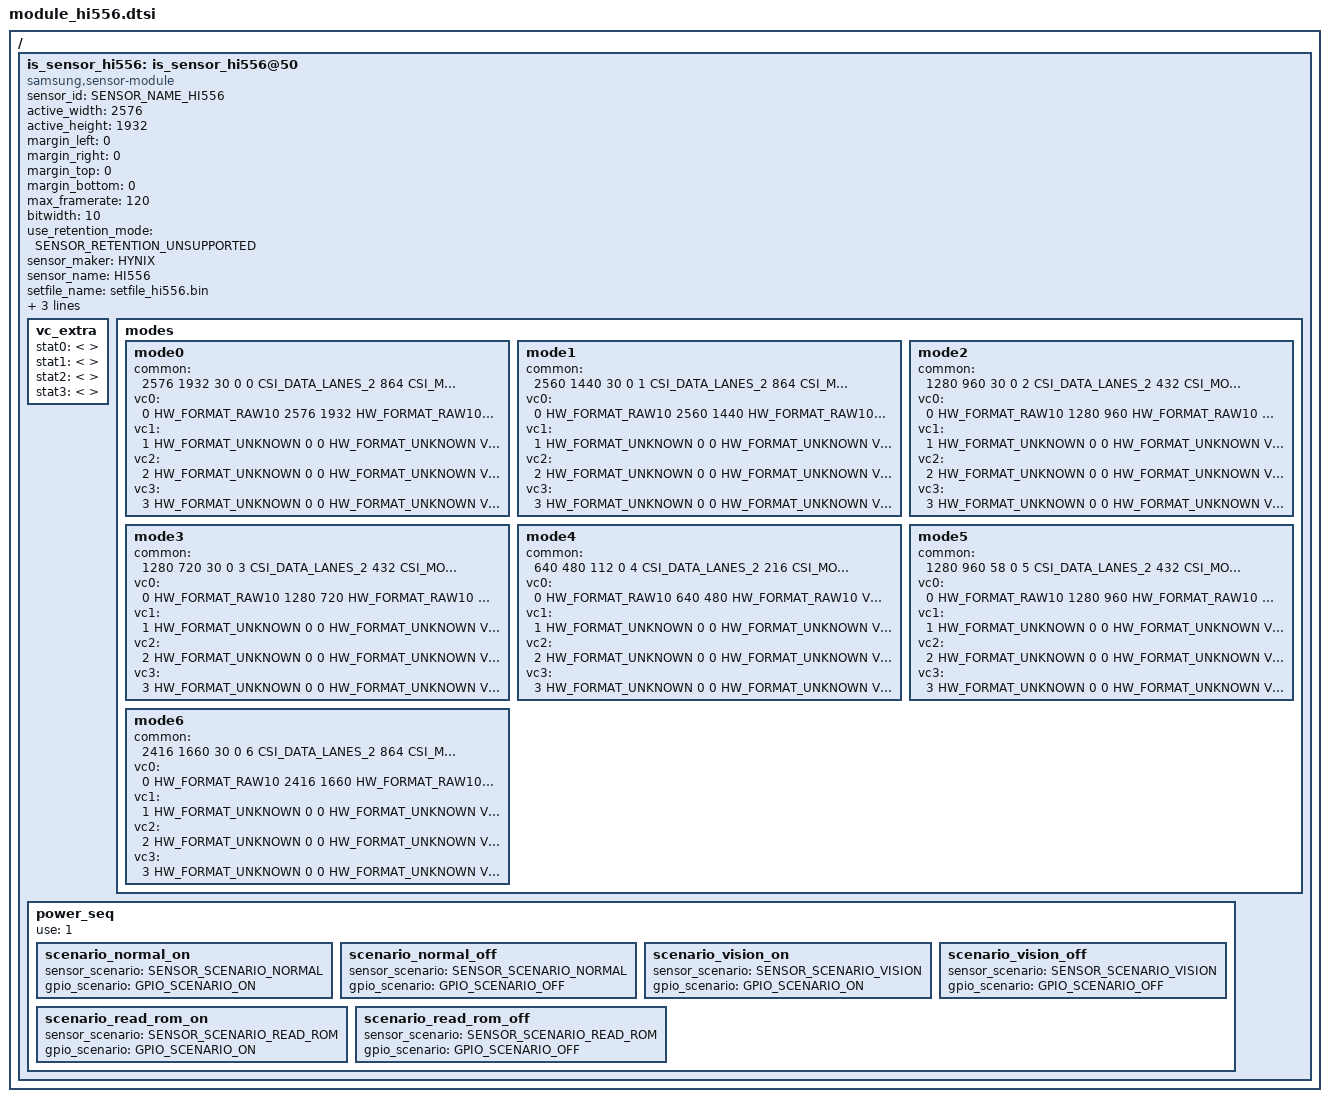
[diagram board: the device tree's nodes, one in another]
/*
 * SAMSUNG EXYNOSxxxx board camera device tree source
 *
 * Copyright (c) 2022 Samsung Electronics Co., Ltd.
 *		http://www.samsung.com
 *
 * This program is free software; you can redistribute it and/or modify
 * it under the terms of the GNU General Public License version 2 as
 * published by the Free Software Foundation.
 */

#include <dt-bindings/camera/exynos_is_dt.h>

#ifndef USE_VENDOR_PWR_PIN_NAME
#define HI556_IOVDD	<>
#define HI556_AVDD	<>
#define HI556_DVDD	<>
#endif

/ {
	fragment@camera {
		target-path = "/";
		__overlay__ {
			is_sensor_hi556: is_sensor_hi556@50 {
				compatible = "samsung,sensor-module";

				/* common */
				sensor_id = <SENSOR_NAME_HI556>;
				active_width = <2576>;
				active_height = <1932>;
				margin_left = <0>;
				margin_right = <0>;
				margin_top = <0>;
				margin_bottom = <0>;
				max_framerate = <120>;
				bitwidth = <10>;
				use_retention_mode = <SENSOR_RETENTION_UNSUPPORTED>;
				sensor_maker = "HYNIX";
				sensor_name = "HI556";
				setfile_name = "setfile_hi556.bin";

				hi556_iovdd-supply = HI556_IOVDD;
				hi556_avdd-supply = HI556_AVDD;
				hi556_dvdd-supply = HI556_DVDD;
				status = "okay";

				vc_extra {
					/* ex) statX = <stat_type, sensor_mode, max_width, max_height, max_element> */
					stat0 = </* not avaliable */>;	/* VC_BUF_DATA_TYPE_SENSOR_STAT1 */
					stat1 = </* not avaliable */>;	/* VC_BUF_DATA_TYPE_GENERAL_STAT1 */
					stat2 = </* not avaliable */>;	/* VC_BUF_DATA_TYPE_SENSOR_STAT2 */
					stat3 = </* not avaliable */>;	/* VC_BUF_DATA_TYPE_GENERAL_STAT2 */
				};

				/* sensor modes */
				modes {
						/* common = <width, height, fps, settle, mode, lane, speed, interleave, lrte, pd_mode> */
						/* vcX = <map, hwformat, width, height, hwformat, type, width, height> */
					/* Full Crop(2576x1932) 4:3 */
					mode0 {
						common = <2576 1932 30 0 0 CSI_DATA_LANES_2 864 CSI_MODE_CH0_ONLY LRTE_DISABLE PD_NONE EX_NONE>;
						vc0 = </* in */ 0 HW_FORMAT_RAW10 2576 1932	/* out */ HW_FORMAT_RAW10 VC_NOTHING 0 0>;
						vc1 = </* in */ 1 HW_FORMAT_UNKNOWN 0 0		/* out */ HW_FORMAT_UNKNOWN VC_NOTHING 0 0>;
						vc2 = </* in */ 2 HW_FORMAT_UNKNOWN 0 0		/* out */ HW_FORMAT_UNKNOWN VC_NOTHING 0 0>;
						vc3 = </* in */ 3 HW_FORMAT_UNKNOWN 0 0		/* out */ HW_FORMAT_UNKNOWN VC_NOTHING 0 0>;
					};
					mode1 {
						common = <2560 1440 30 0 1 CSI_DATA_LANES_2 864 CSI_MODE_CH0_ONLY LRTE_DISABLE PD_NONE EX_NONE>;
						vc0 = </* in */ 0 HW_FORMAT_RAW10 2560 1440	/* out */ HW_FORMAT_RAW10 VC_NOTHING 0 0>;
						vc1 = </* in */ 1 HW_FORMAT_UNKNOWN 0 0		/* out */ HW_FORMAT_UNKNOWN VC_NOTHING 0 0>;
						vc2 = </* in */ 2 HW_FORMAT_UNKNOWN 0 0		/* out */ HW_FORMAT_UNKNOWN VC_NOTHING 0 0>;
						vc3 = </* in */ 3 HW_FORMAT_UNKNOWN 0 0		/* out */ HW_FORMAT_UNKNOWN VC_NOTHING 0 0>;
					};
					mode2 {
						common = <1280 960 30 0 2 CSI_DATA_LANES_2 432 CSI_MODE_CH0_ONLY LRTE_DISABLE PD_NONE EX_NONE>;
						vc0 = </* in */ 0 HW_FORMAT_RAW10 1280 960	/* out */ HW_FORMAT_RAW10 VC_NOTHING 0 0>;
						vc1 = </* in */ 1 HW_FORMAT_UNKNOWN 0 0		/* out */ HW_FORMAT_UNKNOWN VC_NOTHING 0 0>;
						vc2 = </* in */ 2 HW_FORMAT_UNKNOWN 0 0		/* out */ HW_FORMAT_UNKNOWN VC_NOTHING 0 0>;
						vc3 = </* in */ 3 HW_FORMAT_UNKNOWN 0 0		/* out */ HW_FORMAT_UNKNOWN VC_NOTHING 0 0>;
					};
					mode3 {
						common = <1280 720 30 0 3 CSI_DATA_LANES_2 432 CSI_MODE_CH0_ONLY LRTE_DISABLE PD_NONE EX_NONE>;
						vc0 = </* in */ 0 HW_FORMAT_RAW10 1280 720	/* out */ HW_FORMAT_RAW10 VC_NOTHING 0 0>;
						vc1 = </* in */ 1 HW_FORMAT_UNKNOWN 0 0		/* out */ HW_FORMAT_UNKNOWN VC_NOTHING 0 0>;
						vc2 = </* in */ 2 HW_FORMAT_UNKNOWN 0 0		/* out */ HW_FORMAT_UNKNOWN VC_NOTHING 0 0>;
						vc3 = </* in */ 3 HW_FORMAT_UNKNOWN 0 0		/* out */ HW_FORMAT_UNKNOWN VC_NOTHING 0 0>;
					};
					mode4 {
						common = <640 480 112 0 4 CSI_DATA_LANES_2 216 CSI_MODE_CH0_ONLY LRTE_DISABLE PD_NONE EX_NONE>;
						vc0 = </* in */ 0 HW_FORMAT_RAW10 640 480	/* out */ HW_FORMAT_RAW10 VC_NOTHING 0 0>;
						vc1 = </* in */ 1 HW_FORMAT_UNKNOWN 0 0		/* out */ HW_FORMAT_UNKNOWN VC_NOTHING 0 0>;
						vc2 = </* in */ 2 HW_FORMAT_UNKNOWN 0 0		/* out */ HW_FORMAT_UNKNOWN VC_NOTHING 0 0>;
						vc3 = </* in */ 3 HW_FORMAT_UNKNOWN 0 0		/* out */ HW_FORMAT_UNKNOWN VC_NOTHING 0 0>;
					};
					mode5 {
						common = <1280 960 58 0 5 CSI_DATA_LANES_2 432 CSI_MODE_CH0_ONLY LRTE_DISABLE PD_NONE EX_NONE>;
						vc0 = </* in */ 0 HW_FORMAT_RAW10 1280 960	/* out */ HW_FORMAT_RAW10 VC_NOTHING 0 0>;
						vc1 = </* in */ 1 HW_FORMAT_UNKNOWN 0 0		/* out */ HW_FORMAT_UNKNOWN VC_NOTHING 0 0>;
						vc2 = </* in */ 2 HW_FORMAT_UNKNOWN 0 0		/* out */ HW_FORMAT_UNKNOWN VC_NOTHING 0 0>;
						vc3 = </* in */ 3 HW_FORMAT_UNKNOWN 0 0		/* out */ HW_FORMAT_UNKNOWN VC_NOTHING 0 0>;
					};
					mode6 {
						common = <2416 1660 30 0 6 CSI_DATA_LANES_2 864 CSI_MODE_CH0_ONLY LRTE_DISABLE PD_NONE EX_NONE>;
						vc0 = </* in */ 0 HW_FORMAT_RAW10 2416 1660	/* out */ HW_FORMAT_RAW10 VC_NOTHING 0 0>;
						vc1 = </* in */ 1 HW_FORMAT_UNKNOWN 0 0		/* out */ HW_FORMAT_UNKNOWN VC_NOTHING 0 0>;
						vc2 = </* in */ 2 HW_FORMAT_UNKNOWN 0 0		/* out */ HW_FORMAT_UNKNOWN VC_NOTHING 0 0>;
						vc3 = </* in */ 3 HW_FORMAT_UNKNOWN 0 0		/* out */ HW_FORMAT_UNKNOWN VC_NOTHING 0 0>;
					};

				};

				power_seq {
					use = <1>;
					scenario_normal_on {
						sensor_scenario = <SENSOR_SCENARIO_NORMAL>;
						gpio_scenario = <GPIO_SCENARIO_ON>;

						/* A start node number should be over the 10 for reserved number 0~9. */
						/* pname = "name"; pin = <act value dealy voltage>; gpio = <gpx# # 0x1>; */
					};

					scenario_normal_off {
						sensor_scenario = <SENSOR_SCENARIO_NORMAL>;
						gpio_scenario = <GPIO_SCENARIO_OFF>;

						/* A start node number should be over the 10 for reserved number 0~9. */
						/* pname = "name"; pin = <act value dealy voltage>; gpio = <gpx# # 0x1>; */
					};

					scenario_vision_on {
						sensor_scenario = <SENSOR_SCENARIO_VISION>;
						gpio_scenario = <GPIO_SCENARIO_ON>;

						/* A start node number should be over the 10 for reserved number 0~9. */
						/* pname = "name"; pin = <act value dealy voltage>; gpio = <gpx# # 0x1>; */
					};

					scenario_vision_off {
						sensor_scenario = <SENSOR_SCENARIO_VISION>;
						gpio_scenario = <GPIO_SCENARIO_OFF>;

						/* A start node number should be over the 10 for reserved number 0~9. */
						/* pname = "name"; pin = <act value dealy voltage>; gpio = <gpx# # 0x1>; */
					};

					scenario_read_rom_on {
						sensor_scenario = <SENSOR_SCENARIO_READ_ROM>;
						gpio_scenario = <GPIO_SCENARIO_ON>;
					};

					scenario_read_rom_off {
						sensor_scenario = <SENSOR_SCENARIO_READ_ROM>;
						gpio_scenario = <GPIO_SCENARIO_OFF>;
					};
				};
			};
		}; /* end of __overlay__ */
	}; /* end of fragment */
}; /* end of root */
